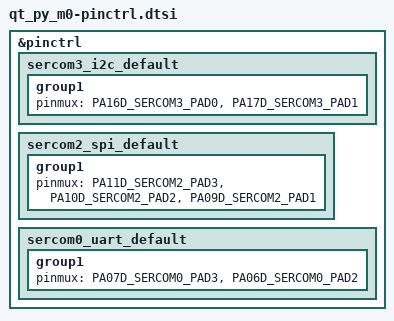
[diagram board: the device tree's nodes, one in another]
/*
 * Copyright (c) 2025 Lucian Copeland for Adafruit Industries
 * SPDX-License-Identifier: Apache-2.0
 */

#include <dt-bindings/pinctrl/samd21-da1eXabcd-pinctrl.h>

&pinctrl {
	sercom3_i2c_default: sercom3_i2c_default {
		group1 {
			pinmux = <PA16D_SERCOM3_PAD0>,
				 <PA17D_SERCOM3_PAD1>;
		};
	};

	sercom2_spi_default: sercom2_spi_default {
		group1 {
			pinmux = <PA11D_SERCOM2_PAD3>,
				 <PA10D_SERCOM2_PAD2>,
				 <PA09D_SERCOM2_PAD1>;
		};
	};

	sercom0_uart_default: sercom0_uart_default {
		group1 {
			pinmux = <PA07D_SERCOM0_PAD3>,
				 <PA06D_SERCOM0_PAD2>;
		};
	};
};
